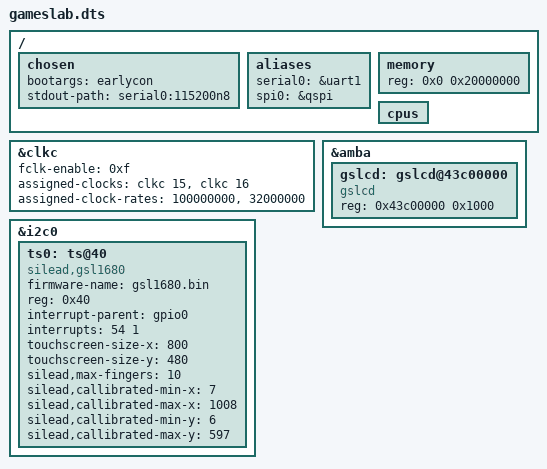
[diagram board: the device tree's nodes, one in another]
/*
 * CAUTION: This file is automatically generated by Xilinx.
 * Version: HSI 2017.2
 * Today is: Sun Jul  9 01:38:35 2017
*/


/dts-v1/;
/include/ "zynq-7000.dtsi"
/include/ "pcw.dtsi"
/ {
	chosen {
		bootargs = "earlycon";
		stdout-path = "serial0:115200n8";
	};
	aliases {
		serial0 = &uart1;
		spi0 = &qspi;
	};
	memory {
		device_type = "memory";
		reg = <0x0 0x20000000>;
	};
	cpus {
	};
};
&clkc {
	fclk-enable = <0xf>;
    assigned-clocks = <&clkc 15>, <&clkc 16>;
    assigned-clock-rates = <100000000>, <32000000>;
};
&i2c0 {
    ts0: ts@40 {
        compatible = "silead,gsl1680";
        firmware-name = "gsl1680.bin";
        reg = <0x40>;
        interrupt-parent = <&gpio0>;
        interrupts = <54 1>; // EMIO0 Active High
        touchscreen-size-x = <800>;
        touchscreen-size-y = <480>;
        silead,max-fingers = <10>;
        silead,callibrated-min-x = <7>;
        silead,callibrated-max-x = <1008>;
        silead,callibrated-min-y = <6>;
        silead,callibrated-max-y = <597>;
    };
};
&amba {
    gslcd: gslcd@43c00000 {
        compatible = "gslcd";
        reg = <0x43c00000 0x1000>;
        status = "okay";
    };
};
